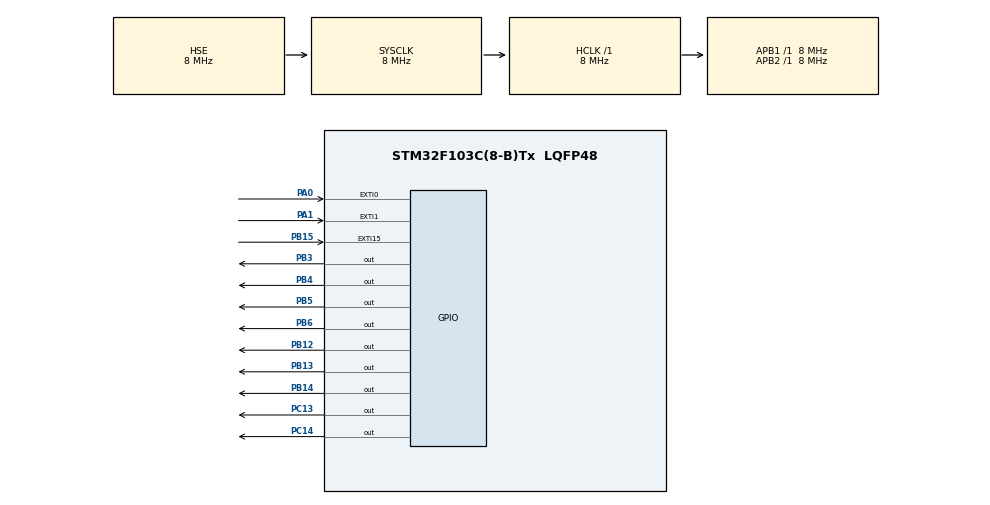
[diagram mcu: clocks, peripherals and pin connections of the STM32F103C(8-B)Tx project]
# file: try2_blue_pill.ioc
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Mcu.Family=STM32F1
Mcu.Name=STM32F103C(8-B)Tx
Mcu.Package=LQFP48
NVIC.PriorityGroup=NVIC_PRIORITYGROUP_4
PA0-WKUP.Signal=GPXTI0
PA1.Signal=GPXTI1
PB12.Signal=GPIO_Output
PB13.Signal=GPIO_Output
PB14.Signal=GPIO_Output
PB15.Signal=GPXTI15
PB3.Signal=GPIO_Output
PB4.Signal=GPIO_Output
PB5.Signal=GPIO_Output
PB6.Signal=GPIO_Output
PC13-TAMPER-RTC.Signal=GPIO_Output
PC14-OSC32_IN.Signal=GPIO_Output
PD0-OSC_IN.Mode=HSE-External-Clock-Source
PD0-OSC_IN.Signal=RCC_OSC_IN
PD1-OSC_OUT.Mode=HSE-External-Clock-Source
PD1-OSC_OUT.Signal=RCC_OSC_OUT
ProjectManager.HeapSize=0x200
ProjectManager.StackSize=0x400
ProjectManager.TargetToolchain=STM32CubeIDE
RCC.AHBFreq_Value=8000000
RCC.APB1Freq_Value=8000000
RCC.APB1TimFreq_Value=8000000
RCC.APB2Freq_Value=8000000
RCC.APB2TimFreq_Value=8000000
RCC.HCLKFreq_Value=8000000
RCC.PLLMUL=RCC_PLL_MUL4
RCC.SYSCLKFreq_VALUE=8000000
RCC.SYSCLKSource=RCC_SYSCLKSOURCE_HSE
RCC.USBFreq_Value=16000000
board=custom

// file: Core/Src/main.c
/* USER CODE BEGIN Header */
/**
  ******************************************************************************
  * @file           : main.c
  * @brief          : Main program body
  ******************************************************************************
  * @attention
  *
  * Copyright (c) 2023 STMicroelectronics.
  * All rights reserved.
  *
  * This software is licensed under terms that can be found in the LICENSE file
  * in the root directory of this software component.
  * If no LICENSE file comes with this software, it is provided AS-IS.
  *
  ******************************************************************************
  */
/* USER CODE END Header */
#include "main.h"
#include "gpio.h"

void SystemClock_Config(void);

int main(void)
{

  /* MCU Configuration--------------------------------------------------------*/

  /* Reset of all peripherals, Initializes the Flash interface and the Systick. */
  HAL_Init();

  /* Configure the system clock */
  SystemClock_Config();

  /* Initialize all configured peripherals */
  MX_GPIO_Init();

  /* Infinite loop */
  /* USER CODE BEGIN WHILE */
  while (1)
  {	//B6.5.12.13.14
	  HAL_GPIO_WritePin(GPIOC, GPIO_PIN_13, GPIO_PIN_RESET);
	   HAL_GPIO_WritePin(GPIOB, GPIO_PIN_12|GPIO_PIN_13|GPIO_PIN_14|GPIO_PIN_3
	                           |GPIO_PIN_4|GPIO_PIN_5|GPIO_PIN_6, GPIO_PIN_RESET);
	   HAL_Delay(500);

		  HAL_GPIO_WritePin(GPIOC, GPIO_PIN_13, GPIO_PIN_SET);
		   HAL_GPIO_WritePin(GPIOB, GPIO_PIN_12|GPIO_PIN_13|GPIO_PIN_14|GPIO_PIN_3
		                           |GPIO_PIN_4|GPIO_PIN_5|GPIO_PIN_6, GPIO_PIN_SET);
		   HAL_Delay(500);

    /* USER CODE END WHILE */

  }
}

void SystemClock_Config(void)
{
  RCC_OscInitTypeDef RCC_OscInitStruct = {0};
  RCC_ClkInitTypeDef RCC_ClkInitStruct = {0};

  /** Initializes the RCC Oscillators according to the specified parameters
  * in the RCC_OscInitTypeDef structure.
  */
  RCC_OscInitStruct.OscillatorType = RCC_OSCILLATORTYPE_HSE;
  RCC_OscInitStruct.HSEState = RCC_HSE_BYPASS;
  RCC_OscInitStruct.PLL.PLLState = RCC_PLL_NONE;
  if (HAL_RCC_OscConfig(&RCC_OscInitStruct) != HAL_OK)
  {
    Error_Handler();
  }

  /** Initializes the CPU, AHB and APB buses clocks
  */
  RCC_ClkInitStruct.ClockType = RCC_CLOCKTYPE_HCLK|RCC_CLOCKTYPE_SYSCLK
                              |RCC_CLOCKTYPE_PCLK1|RCC_CLOCKTYPE_PCLK2;
  RCC_ClkInitStruct.SYSCLKSource = RCC_SYSCLKSOURCE_HSE;
  RCC_ClkInitStruct.AHBCLKDivider = RCC_SYSCLK_DIV1;
  RCC_ClkInitStruct.APB1CLKDivider = RCC_HCLK_DIV1;
  RCC_ClkInitStruct.APB2CLKDivider = RCC_HCLK_DIV1;

  if (HAL_RCC_ClockConfig(&RCC_ClkInitStruct, FLASH_LATENCY_0) != HAL_OK)
  {
    Error_Handler();
  }
}

void Error_Handler(void)
{
  __disable_irq();
  while (1)
  {
  }
}
